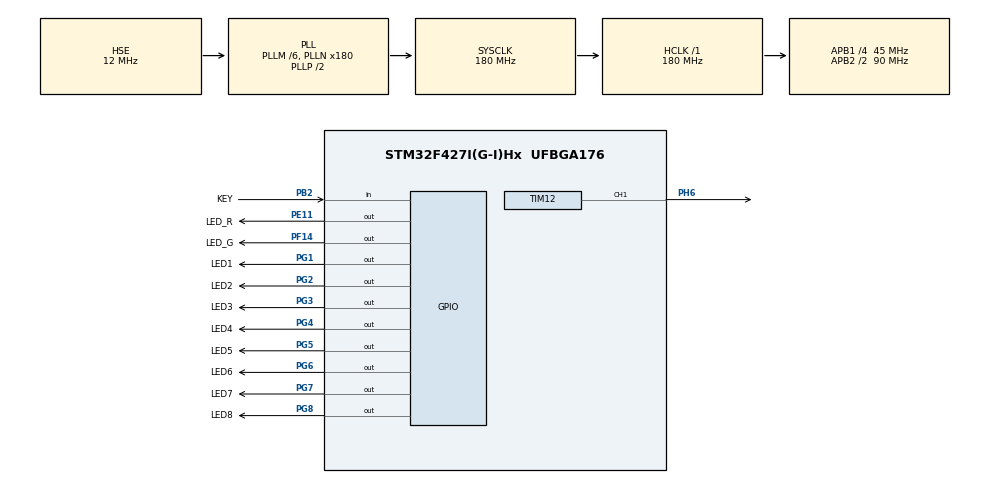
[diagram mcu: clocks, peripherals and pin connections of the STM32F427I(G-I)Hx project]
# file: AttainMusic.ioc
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Mcu.Family=STM32F4
Mcu.Name=STM32F427I(G-I)Hx
Mcu.Package=UFBGA176
NVIC.PriorityGroup=NVIC_PRIORITYGROUP_4
PA13.Mode=Serial_Wire
PA13.Signal=SYS_JTMS-SWDIO
PA14.Mode=Serial_Wire
PA14.Signal=SYS_JTCK-SWCLK
PB2/BOOT1.GPIO_Label=KEY
PB2/BOOT1.GPIO_PuPd=GPIO_PULLUP
PB2/BOOT1.Signal=GPIO_Input
PE11.GPIO_Label=LED_R
PE11.Signal=GPIO_Output
PF14.GPIO_Label=LED_G
PF14.PinState=GPIO_PIN_SET
PF14.Signal=GPIO_Output
PG1.GPIO_Label=LED1
PG1.Signal=GPIO_Output
PG2.GPIO_Label=LED2
PG2.Signal=GPIO_Output
PG3.GPIO_Label=LED3
PG3.Signal=GPIO_Output
PG4.GPIO_Label=LED4
PG4.Signal=GPIO_Output
PG5.GPIO_Label=LED5
PG5.Signal=GPIO_Output
PG6.GPIO_Label=LED6
PG6.Signal=GPIO_Output
PG7.GPIO_Label=LED7
PG7.Signal=GPIO_Output
PG8.GPIO_Label=LED8
PG8.Signal=GPIO_Output
PH0/OSC_IN.Mode=HSE-External-Oscillator
PH0/OSC_IN.Signal=RCC_OSC_IN
PH1/OSC_OUT.Mode=HSE-External-Oscillator
PH1/OSC_OUT.Signal=RCC_OSC_OUT
PH6.Signal=S_TIM12_CH1
ProjectManager.HeapSize=0x200
ProjectManager.StackSize=0x400
ProjectManager.TargetToolchain=MDK-ARM V5
RCC.48MHZClocksFreq_Value=90000000
RCC.AHBFreq_Value=180000000
RCC.APB1CLKDivider=RCC_HCLK_DIV4
RCC.APB1Freq_Value=45000000
RCC.APB1TimFreq_Value=90000000
RCC.APB2CLKDivider=RCC_HCLK_DIV2
RCC.APB2Freq_Value=90000000
RCC.APB2TimFreq_Value=180000000
RCC.CortexFreq_Value=180000000
RCC.HCLKFreq_Value=180000000
RCC.HSE_VALUE=12000000
RCC.HSI_VALUE=16000000
RCC.LSE_VALUE=32768
RCC.PLLM=6
RCC.PLLN=180
RCC.PLLSourceVirtual=RCC_PLLSOURCE_HSE
RCC.SYSCLKFreq_VALUE=180000000
RCC.SYSCLKSource=RCC_SYSCLKSOURCE_PLLCLK
RCC.VCOOutputFreq_Value=360000000
SH.S_TIM12_CH1.0=TIM12_CH1,PWM Generation1 CH1
TIM12.AutoReloadPreload=TIM_AUTORELOAD_PRELOAD_ENABLE
TIM12.Channel-PWM\ Generation1\ CH1=TIM_CHANNEL_1
TIM12.Period=999
TIM12.Prescaler=89
TIM12.Pulse-PWM\ Generation1\ CH1=0
board=custom

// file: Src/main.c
/* USER CODE BEGIN Header */
/**
  ******************************************************************************
  * @file           : main.c
  * @brief          : Main program body
  ******************************************************************************
  * @attention
  *
  * <h2><center>&copy; Copyright (c) 2019 STMicroelectronics.
  * All rights reserved.</center></h2>
  *
  * This software component is licensed by ST under BSD 3-Clause license,
  * the "License"; You may not use this file except in compliance with the
  * License. You may obtain a copy of the License at:
  *                        opensource.org/licenses/BSD-3-Clause
  *
  ******************************************************************************
  */
/* USER CODE END Header */

#include "main.h"
#include "tim.h"
#include "gpio.h"

/* USER CODE BEGIN Includes */
#include "MusicLab.h"
/* USER CODE END Includes */

void SystemClock_Config(void);

int main(void)
{
  /* USER CODE BEGIN 1 */
  int lenght=0;
  /* USER CODE END 1 */

  /* MCU Configuration--------------------------------------------------------*/

  /* Reset of all peripherals, Initializes the Flash interface and the Systick. */
  HAL_Init();

  /* Configure the system clock */
  SystemClock_Config();

  /* Initialize all configured peripherals */
  MX_GPIO_Init();
  MX_TIM12_Init();
  /* USER CODE BEGIN 2 */
  HAL_TIM_PWM_Start(&htim12, TIM_CHANNEL_1);
  /* USER CODE END 2 */

  /* Infinite loop */
  /* USER CODE BEGIN WHILE */

		/*
			Motherland     A�� T=2500
			SteelTorrent   C�� T=700
			HappyBirthday  A�� T=3000
			CastleInTheSky A�� T=2700
			TheDawn        A�� T=3000
	*/

  /*������״�С*/
  lenght = sizeof(SteelTorrent)/sizeof(SteelTorrent[0]);
  while (1)
  {
    /* USER CODE END WHILE */

    /* USER CODE BEGIN 3 */
		PlayMusic(SteelTorrent, lenght, C);
		HAL_Delay(10);
  }
  /* USER CODE END 3 */
}

void SystemClock_Config(void)
{
  RCC_OscInitTypeDef RCC_OscInitStruct = {0};
  RCC_ClkInitTypeDef RCC_ClkInitStruct = {0};

  /** Configure the main internal regulator output voltage
  */
  __HAL_RCC_PWR_CLK_ENABLE();
  __HAL_PWR_VOLTAGESCALING_CONFIG(PWR_REGULATOR_VOLTAGE_SCALE1);
  /** Initializes the CPU, AHB and APB busses clocks
  */
  RCC_OscInitStruct.OscillatorType = RCC_OSCILLATORTYPE_HSE;
  RCC_OscInitStruct.HSEState = RCC_HSE_ON;
  RCC_OscInitStruct.PLL.PLLState = RCC_PLL_ON;
  RCC_OscInitStruct.PLL.PLLSource = RCC_PLLSOURCE_HSE;
  RCC_OscInitStruct.PLL.PLLM = 6;
  RCC_OscInitStruct.PLL.PLLN = 180;
  RCC_OscInitStruct.PLL.PLLP = RCC_PLLP_DIV2;
  RCC_OscInitStruct.PLL.PLLQ = 4;
  if (HAL_RCC_OscConfig(&RCC_OscInitStruct) != HAL_OK)
  {
    Error_Handler();
  }
  /** Activate the Over-Drive mode
  */
  if (HAL_PWREx_EnableOverDrive() != HAL_OK)
  {
    Error_Handler();
  }
  /** Initializes the CPU, AHB and APB busses clocks
  */
  RCC_ClkInitStruct.ClockType = RCC_CLOCKTYPE_HCLK|RCC_CLOCKTYPE_SYSCLK
                              |RCC_CLOCKTYPE_PCLK1|RCC_CLOCKTYPE_PCLK2;
  RCC_ClkInitStruct.SYSCLKSource = RCC_SYSCLKSOURCE_PLLCLK;
  RCC_ClkInitStruct.AHBCLKDivider = RCC_SYSCLK_DIV1;
  RCC_ClkInitStruct.APB1CLKDivider = RCC_HCLK_DIV4;
  RCC_ClkInitStruct.APB2CLKDivider = RCC_HCLK_DIV2;

  if (HAL_RCC_ClockConfig(&RCC_ClkInitStruct, FLASH_LATENCY_5) != HAL_OK)
  {
    Error_Handler();
  }
}

void Error_Handler(void)
{
}

/************************ (C) COPYRIGHT STMicroelectronics *****END OF FILE****/
